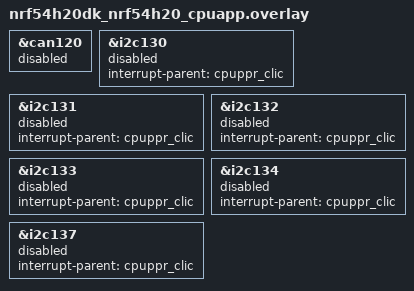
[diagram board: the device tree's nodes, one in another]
/*
 * Copyright (c) 2025 Nordic Semiconductor ASA
 *
 * SPDX-License-Identifier: LicenseRef-Nordic-5-Clause
 */

&can120 {
	status = "disabled";
};

&i2c130 {
	status = "reserved";
	interrupt-parent = <&cpuppr_clic>;
};

&i2c131 {
	status = "reserved";
	interrupt-parent = <&cpuppr_clic>;
};

&i2c132 {
	status = "reserved";
	interrupt-parent = <&cpuppr_clic>;
};

&i2c133 {
	status = "reserved";
	interrupt-parent = <&cpuppr_clic>;
};

&i2c134 {
	status = "reserved";
	interrupt-parent = <&cpuppr_clic>;
};

&i2c137 {
	status = "reserved";
	interrupt-parent = <&cpuppr_clic>;
};
